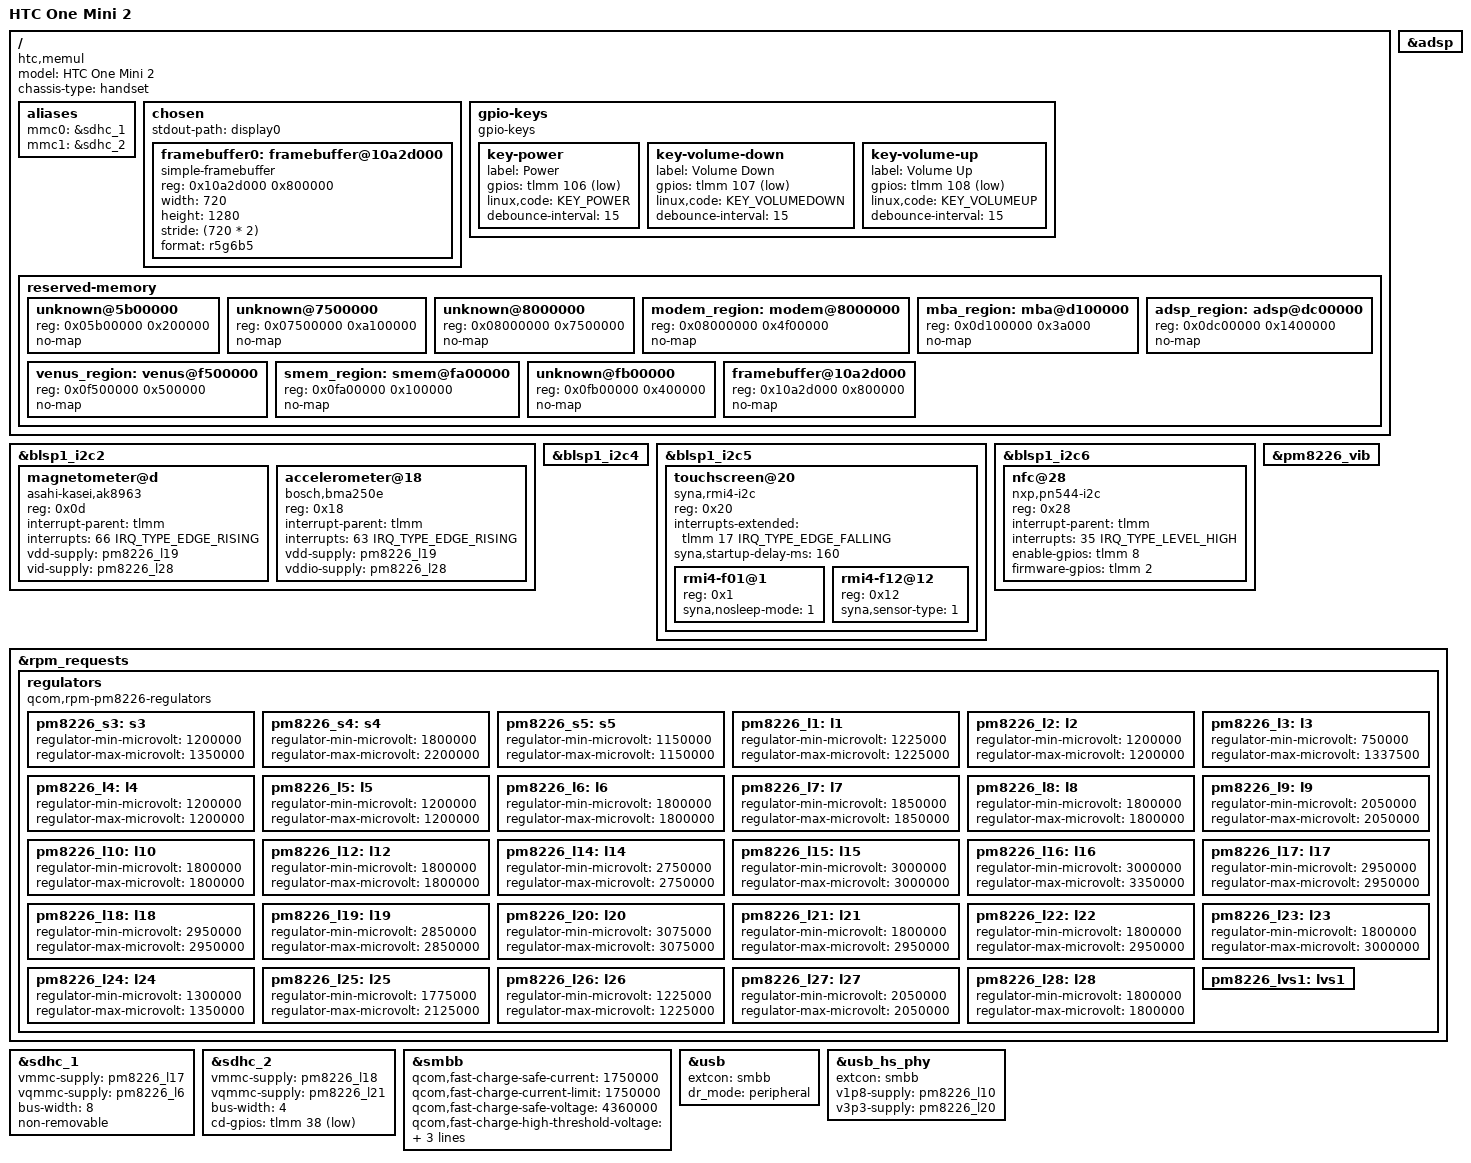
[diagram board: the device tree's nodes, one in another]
// SPDX-License-Identifier: BSD-3-Clause
/*
 * Copyright (c) 2023, Luca Weiss <luca@z3ntu.xyz>
 */

/dts-v1/;

#include "qcom-msm8226.dtsi"
#include "qcom-pm8226.dtsi"

/delete-node/ &adsp_region;
/delete-node/ &smem_region;

/ {
	model = "HTC One Mini 2";
	compatible = "htc,memul", "qcom,msm8926";
	chassis-type = "handset";

	aliases {
		mmc0 = &sdhc_1; /* SDC1 eMMC slot */
		mmc1 = &sdhc_2; /* SDC2 SD card slot */
	};

	chosen {
		#address-cells = <1>;
		#size-cells = <1>;
		ranges;

		stdout-path = "display0";

		framebuffer0: framebuffer@10a2d000 {
			compatible = "simple-framebuffer";
			reg = <0x10a2d000 0x800000>; // TODO: Fix size
			width = <720>;
			height = <1280>;
			stride = <(720 * 2)>;
			format = "r5g6b5";
		};
	};

	gpio-keys {
		compatible = "gpio-keys";

		key-power {
			label = "Power";
			gpios = <&tlmm 106 GPIO_ACTIVE_LOW>;
			linux,code = <KEY_POWER>;
			debounce-interval = <15>;
		};

		key-volume-down {
			label = "Volume Down";
			gpios = <&tlmm 107 GPIO_ACTIVE_LOW>;
			linux,code = <KEY_VOLUMEDOWN>;
			debounce-interval = <15>;
		};

		key-volume-up {
			label = "Volume Up";
			gpios = <&tlmm 108 GPIO_ACTIVE_LOW>;
			linux,code = <KEY_VOLUMEUP>;
			debounce-interval = <15>;
		};
	};

/*
memul:/ # cat /sys/kernel/debug/memblock/memory
   0: 0x00000000..0x05afffff
   1: 0x05d00000..0x074fffff
   2: 0x11600000..0x3f9fffff
memul:/ # cat /sys/kernel/debug/memblock/reserved
   0: 0x00000000..0x00007fff
   1: 0x00100000..0x01522f1b
   2: 0x01e00000..0x01e2e401
   3: 0x02008000..0x02160d47
   4: 0x05b00000..0x05bcffff
   5: 0x2b400000..0x2fffffff
   6: 0x302cb000..0x302fefff
   7: 0x302ffda0..0x302fffff

[140] MDP continuous splash detected: pipe RGB_0, base: 0x10a2d000, stride: 1440, src: 720x1280 (0,0), img: 720x1280, out: 720x1280 (0,0), format: 0x22216 (bpp: 2)

Address and Size of Hole
qcom,memblock-remove = <0x8000000 0x7500000 0xfa00000 0x500000>;

[    5.667433] pil-q6v5-mss fc880000.qcom,mss: mba: loading from 0x0d100000 to 0x0d13a000
[    5.671198] pil-q6v5-lpass fe200000.qcom,lpass: adsp: loading from 0x0dc00000 to 0x0f000000
[    5.742635] pil-q6v5-mss fc880000.qcom,mss: modem: loading from 0x08000000 to 0x0cf00000
[   19.441562] pil_venus fdce0000.qcom,venus: venus: loading from 0x0f500000 to 0x0fa00000
*/

/*
[    0.000000] OF: reserved mem: OVERLAP DETECTED!
[    0.000000] unknown@7500000 (0x07500000--0x11600000) overlaps with modem@8000000 (0x08000000--0x0cf00000)
[    0.000000] OF: reserved mem: OVERLAP DETECTED!
[    0.000000] modem@8000000 (0x08000000--0x0cf00000) overlaps with unknown@8000000 (0x08000000--0x0f500000)
[    0.000000] OF: reserved mem: OVERLAP DETECTED!
[    0.000000] unknown@8000000 (0x08000000--0x0f500000) overlaps with mba@d100000 (0x0d100000--0x0d13a000)
*/
	reserved-memory {
		unknown@5b00000 {
			//0x5b00000 - 0x5d00000
			reg = <0x05b00000 0x200000>;
			no-map;
		};
		unknown@7500000 { // TODO: giant region that contains most others
			//0x7500000 - 0x11600000
			reg = <0x07500000 0xa100000>;
			no-map;
		};

		unknown@8000000 { // TODO: pretty big region that contains many others
			reg = <0x08000000 0x7500000>; // until 0x0f500000
			no-map;
		};
		modem_region: modem@8000000 {
			reg = <0x08000000 0x4f00000>;
			no-map;
		};
		mba_region: mba@d100000 {
			reg = <0x0d100000 0x3a000>;
			no-map;
		};
		adsp_region: adsp@dc00000 {
			reg = <0x0dc00000 0x1400000>;
			no-map;
		};
		venus_region: venus@f500000 {
			reg = <0x0f500000 0x500000>;
			no-map;
		};
		smem_region: smem@fa00000 {
			reg = <0x0fa00000 0x100000>;
			no-map;
		};
		unknown@fb00000 {
			reg = <0x0fb00000 0x400000>;
			no-map;
		};
		framebuffer@10a2d000 {
			reg = <0x10a2d000 0x800000>; // TODO: Fix size
			no-map;
		};
	};
};

&adsp {
	status = "okay";
};

&blsp1_i2c2 {
	status = "okay";

	// akm8963 @ 0d -- OK!
	magnetometer@d {
		compatible = "asahi-kasei,ak8963";
		reg = <0x0d>;
		interrupt-parent = <&tlmm>;
		interrupts = <66 IRQ_TYPE_EDGE_RISING>;
		vdd-supply = <&pm8226_l19>;
		vid-supply = <&pm8226_l28>;
	};

	// bma250_bosch @ 18 -- OK!
	accelerometer@18 {
		compatible = "bosch,bma250e";
		reg = <0x18>;
		interrupt-parent = <&tlmm>;
		interrupts = <63 IRQ_TYPE_EDGE_RISING>;
		vdd-supply = <&pm8226_l19>;
		vddio-supply = <&pm8226_l28>;
	};
};

&blsp1_i2c4 {
	status = "okay";
	// ?? @ 0e
	// tfa9887 @ 34
	// tfa9887l @ 35
	// rt5501 @ 52 ?
};

&blsp1_i2c5 {
	status = "okay";
	// himax @ 48 ?

	// synaptics @ 20 ?
	touchscreen@20 {
		compatible = "syna,rmi4-i2c";
		reg = <0x20>;

		interrupts-extended = <&tlmm 17 IRQ_TYPE_EDGE_FALLING>;
		//vdd-supply = <&pm8226_l19>;
		//vio-supply = <&pm8226_lvs1>;

		//pinctrl-names = "default";
		//pinctrl-0 = <&touch_default_state>;

		syna,startup-delay-ms = <160>;

		#address-cells = <1>;
		#size-cells = <0>;

		rmi4-f01@1 {
			reg = <0x1>;
			syna,nosleep-mode = <1>;
		};

		rmi4-f12@12 {
			reg = <0x12>;
			syna,sensor-type = <1>;
		};
	};
};

&blsp1_i2c6 {
	status = "okay";
	// ncp6924 @ 10 (camera regulators)
	// tps61310 @ 33 (flashlight/torch) -- mfd/tps6105x.txt
	// tps_65132 @ 3e ? (panel regulator)

	// pn544_nfc @ 28 -- OK! but fails with neard
	// [  130.388553] i2c: 00000000: 05 f9 04 00 c3 e5
	// [  130.389765] pn544_hci_i2c 3-0028: NFC: invalid len byte
	nfc@28 {
		compatible = "nxp,pn544-i2c";
		reg = <0x28>;

		interrupt-parent = <&tlmm>;
		interrupts = <35 IRQ_TYPE_LEVEL_HIGH>;

		enable-gpios = <&tlmm 8 GPIO_ACTIVE_HIGH>;
		firmware-gpios = <&tlmm 2 GPIO_ACTIVE_HIGH>;
	};
};

&pm8226_vib {
	status = "okay";
};

&rpm_requests {
	regulators {
		compatible = "qcom,rpm-pm8226-regulators";

		pm8226_s3: s3 {
			regulator-min-microvolt = <1200000>;
			regulator-max-microvolt = <1350000>;
		};
		pm8226_s4: s4 {
			regulator-min-microvolt = <1800000>;
			regulator-max-microvolt = <2200000>;
		};
		pm8226_s5: s5 {
			regulator-min-microvolt = <1150000>;
			regulator-max-microvolt = <1150000>;
		};

		pm8226_l1: l1 {
			regulator-min-microvolt = <1225000>;
			regulator-max-microvolt = <1225000>;
		};
		pm8226_l2: l2 {
			regulator-min-microvolt = <1200000>;
			regulator-max-microvolt = <1200000>;
		};
		pm8226_l3: l3 {
			regulator-min-microvolt = <750000>;
			regulator-max-microvolt = <1337500>;
		};
		pm8226_l4: l4 {
			regulator-min-microvolt = <1200000>;
			regulator-max-microvolt = <1200000>;
		};
		pm8226_l5: l5 {
			regulator-min-microvolt = <1200000>;
			regulator-max-microvolt = <1200000>;
		};
		pm8226_l6: l6 {
			regulator-min-microvolt = <1800000>;
			regulator-max-microvolt = <1800000>;
		};
		pm8226_l7: l7 {
			regulator-min-microvolt = <1850000>;
			regulator-max-microvolt = <1850000>;
		};
		pm8226_l8: l8 {
			regulator-min-microvolt = <1800000>;
			regulator-max-microvolt = <1800000>;
		};
		pm8226_l9: l9 {
			regulator-min-microvolt = <2050000>;
			regulator-max-microvolt = <2050000>;
		};
		pm8226_l10: l10 {
			regulator-min-microvolt = <1800000>;
			regulator-max-microvolt = <1800000>;
		};
		pm8226_l12: l12 {
			regulator-min-microvolt = <1800000>;
			regulator-max-microvolt = <1800000>;
		};
		pm8226_l14: l14 {
			regulator-min-microvolt = <2750000>;
			regulator-max-microvolt = <2750000>;
		};
		pm8226_l15: l15 {
			regulator-min-microvolt = <3000000>;
			regulator-max-microvolt = <3000000>;
		};
		pm8226_l16: l16 {
			regulator-min-microvolt = <3000000>;
			regulator-max-microvolt = <3350000>;
		};
		pm8226_l17: l17 {
			regulator-min-microvolt = <2950000>;
			regulator-max-microvolt = <2950000>;
		};
		pm8226_l18: l18 {
			regulator-min-microvolt = <2950000>;
			regulator-max-microvolt = <2950000>;
		};
		pm8226_l19: l19 {
			regulator-min-microvolt = <2850000>;
			regulator-max-microvolt = <2850000>;
		};
		pm8226_l20: l20 {
			regulator-min-microvolt = <3075000>;
			regulator-max-microvolt = <3075000>;
		};
		pm8226_l21: l21 {
			regulator-min-microvolt = <1800000>;
			regulator-max-microvolt = <2950000>;
		};
		pm8226_l22: l22 {
			regulator-min-microvolt = <1800000>;
			regulator-max-microvolt = <2950000>;
		};
		pm8226_l23: l23 {
			regulator-min-microvolt = <1800000>;
			regulator-max-microvolt = <3000000>;
		};
		pm8226_l24: l24 {
			regulator-min-microvolt = <1300000>;
			regulator-max-microvolt = <1350000>;
		};
		pm8226_l25: l25 {
			regulator-min-microvolt = <1775000>;
			regulator-max-microvolt = <2125000>;
		};
		pm8226_l26: l26 {
			regulator-min-microvolt = <1225000>;
			regulator-max-microvolt = <1225000>;
		};
		pm8226_l27: l27 {
			regulator-min-microvolt = <2050000>;
			regulator-max-microvolt = <2050000>;
		};
		pm8226_l28: l28 {
			regulator-min-microvolt = <1800000>;
			regulator-max-microvolt = <1800000>;
		};

		pm8226_lvs1: lvs1 {};
	};
};

&sdhc_1 {
	vmmc-supply = <&pm8226_l17>;
	vqmmc-supply = <&pm8226_l6>;

	bus-width = <8>;
	non-removable;

	status = "okay";
};

&sdhc_2 {
	vmmc-supply = <&pm8226_l18>;
	vqmmc-supply = <&pm8226_l21>;

	bus-width = <4>;
	cd-gpios = <&tlmm 38 GPIO_ACTIVE_LOW>;

	status = "okay";
};

&smbb {
	qcom,fast-charge-safe-current = <1750000>;
	qcom,fast-charge-current-limit = <1750000>;
	qcom,fast-charge-safe-voltage = <4360000>;
	qcom,fast-charge-high-threshold-voltage = <4350000>;
	qcom,auto-recharge-threshold-voltage = <4300000>;
	qcom,minimum-input-voltage = <4300000>;
};

&usb {
	extcon = <&smbb>;
	dr_mode = "peripheral";
	status = "okay";
};

&usb_hs_phy {
	extcon = <&smbb>;
	v1p8-supply = <&pm8226_l10>;
	v3p3-supply = <&pm8226_l20>;
};
